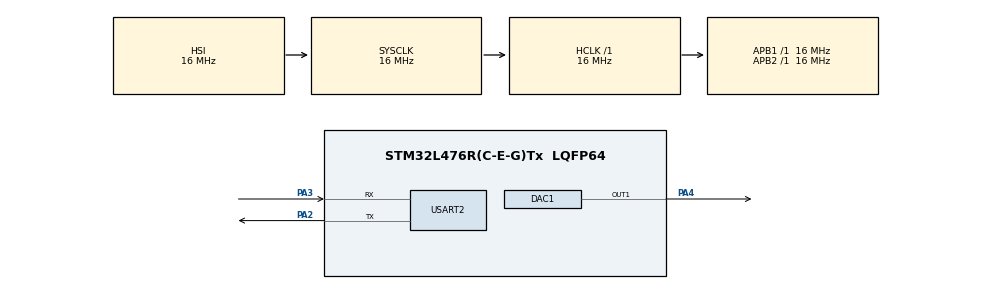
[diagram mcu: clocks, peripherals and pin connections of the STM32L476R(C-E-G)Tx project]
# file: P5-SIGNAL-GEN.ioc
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DAC1.DAC_Trigger-DAC_OUT1=DAC_TRIGGER_T2_TRGO
Dma.DAC_CH1.0.Direction=DMA_MEMORY_TO_PERIPH
Dma.DAC_CH1.0.Instance=DMA1_Channel3
Dma.DAC_CH1.0.MemDataAlignment=DMA_MDATAALIGN_WORD
Dma.DAC_CH1.0.MemInc=DMA_MINC_ENABLE
Dma.DAC_CH1.0.Mode=DMA_CIRCULAR
Dma.DAC_CH1.0.PeriphDataAlignment=DMA_PDATAALIGN_WORD
Dma.DAC_CH1.0.PeriphInc=DMA_PINC_DISABLE
Dma.DAC_CH1.0.Priority=DMA_PRIORITY_HIGH
Dma.Request0=DAC_CH1
Mcu.Family=STM32L4
Mcu.Name=STM32L476R(C-E-G)Tx
Mcu.Package=LQFP64
NVIC.DMA1_Channel3_IRQn=true\:0\:0\:false\:false\:true\:false\:true
NVIC.PriorityGroup=NVIC_PRIORITYGROUP_4
PA2.Mode=Asynchronous
PA2.Signal=USART2_TX
PA3.Mode=Asynchronous
PA3.Signal=USART2_RX
PA4.Signal=COMP_DAC11_group
ProjectManager.HeapSize=0x200
ProjectManager.StackSize=0x400
ProjectManager.TargetToolchain=STM32CubeIDE
RCC.ADCFreq_Value=16000000
RCC.AHBFreq_Value=16000000
RCC.APB1Freq_Value=16000000
RCC.APB1TimFreq_Value=16000000
RCC.APB2Freq_Value=16000000
RCC.APB2TimFreq_Value=16000000
RCC.CortexFreq_Value=16000000
RCC.HCLKFreq_Value=16000000
RCC.HSE_VALUE=8000000
RCC.HSI_VALUE=16000000
RCC.LSE_VALUE=32768
RCC.MSI_VALUE=4000000
RCC.SYSCLKFreq_VALUE=16000000
RCC.SYSCLKSource=RCC_SYSCLKSOURCE_HSI
RCC.USBFreq_Value=16000000
RCC.VCOOutputFreq_Value=32000000
SH.COMP_DAC11_group.0=DAC1_OUT1,DAC_OUT1
TIM2.TIM_MasterOutputTrigger=TIM_TRGO_UPDATE
USART2.VirtualMode-Asynchronous=VM_ASYNC
VP_TIM2_VS_ClockSourceINT.Mode=Internal
board=custom

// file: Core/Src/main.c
/* USER CODE BEGIN Header */
/**
  ******************************************************************************
  * @file           : main.c
  * @brief          : Main program body
  ******************************************************************************
  * @attention
  *
  * <h2><center>&copy; Copyright (c) 2021 STMicroelectronics.
  * All rights reserved.</center></h2>
  *
  * This software component is licensed by ST under BSD 3-Clause license,
  * the "License"; You may not use this file except in compliance with the
  * License. You may obtain a copy of the License at:
  *                        opensource.org/licenses/BSD-3-Clause
  *
  ******************************************************************************
  */
/* USER CODE END Header */
#include "main.h"

/* USER CODE BEGIN Includes */
#include "stdlib.h"
#include "string.h"
#include "stdio.h"
#include "ctype.h"
#include "math.h"
/* USER CODE END Includes */

/* USER CODE BEGIN PTD */
typedef enum {
	SQUARE,
	SINE,
	TRIANGLE
} WaveType;

typedef struct {
	WaveType type;
	int frequency;
	float logic_min;
	float logic_max;
} Wave;
/* USER CODE END PTD */

DAC_HandleTypeDef hdac1;
DMA_HandleTypeDef hdma_dac_ch1;

TIM_HandleTypeDef htim2;

UART_HandleTypeDef huart2;

/* USER CODE BEGIN PV */
uint32_t wave_buffer[WAVE_SIZE_MAX];
uint8_t str[256];
int n;
/* USER CODE END PV */

void SystemClock_Config(void);
static void MX_GPIO_Init(void);
static void MX_DMA_Init(void);
static void MX_DAC1_Init(void);
static void MX_TIM2_Init(void);
static void MX_USART2_UART_Init(void);
/* USER CODE BEGIN PFP */
void wave_gen(Wave* wave);
/* USER CODE END PFP */

int main(void)
{

  /* MCU Configuration--------------------------------------------------------*/

  /* Reset of all peripherals, Initializes the Flash interface and the Systick. */
  HAL_Init();

  /* Configure the system clock */
  SystemClock_Config();

  /* Initialize all configured peripherals */
  MX_GPIO_Init();
  MX_DMA_Init();
  MX_DAC1_Init();
  MX_TIM2_Init();
  MX_USART2_UART_Init();
  /* USER CODE BEGIN 2 */
  n = sprintf((char*) str, "Project 5 - Signal Generator by Chris Abajian (cxa6282@rit.edu)\r\n");
  HAL_UART_Transmit(&huart2, str, n, 100);
  n = sprintf((char*) str, "Starting a 1KHz square wave from 0.0V - 3.3V\r\n");
  HAL_UART_Transmit(&huart2, str, n, 100);
  n = sprintf((char*) str, "Command format: \r\n");
  HAL_UART_Transmit(&huart2, str, n, 100);
  n = sprintf((char*) str, "  > type freq minv maxv\r\n");
  HAL_UART_Transmit(&huart2, str, n, 100);
  // Initialize a 1KHz square wave.
  Wave wave = {SQUARE, 1000, LOGIC_MIN, LOGIC_MAX};
  wave_gen(&wave);
  /* USER CODE END 2 */

  /* Infinite loop */
  /* USER CODE BEGIN WHILE */
  while (1)
  {
    // Prompt
    n = sprintf((char*) str, "> ");
    HAL_UART_Transmit(&huart2, str, n, 100);

	// Wait for incoming command.
    int i = 0;
    uint8_t cmd[128];
	while (1) {
		uint8_t c;
		HAL_UART_Receive(&huart2, &c, 1, 1000000);
		if ((c == '\r') || (c == '\n')) {
			cmd[i] = 0;
			n = sprintf((char*) str, "\r\n");
			HAL_UART_Transmit(&huart2, str, n, 100);
			break;
		} else {
			HAL_UART_Transmit(&huart2, &c, 1, 100);
			cmd[i++] = c;
		}
	}

	// Parse command.
	i = 0;
	char* arg = strtok((char*)cmd, " ");
	while ((arg != NULL) && (i < 4)) {
		switch (i++) {
			// Wave type
			case 0:;
				char c = tolower(arg[0]);
				if (c == 'r') {
					wave.type = SQUARE;
				} else if (c == 's') {
					wave.type = SINE;
				} else if (c == 't') {
					wave.type = TRIANGLE;
				}
				break;
			// Wave frequency
			case 1:;
				int f = atoi(arg);
				if ((f >= WAVE_FREQ_MIN) && (f <= WAVE_FREQ_MAX))
					wave.frequency = f;
				break;
			// Wave minimum logic level
			case 2:;
				float min = atof(arg);
				if ((min >= LOGIC_MIN) && (min < LOGIC_MAX))
					wave.logic_min = min;
				break;
			// Wave maximum logic level
			case 3:;
				float max = atof(arg);
				if ((max > wave.logic_min) && (max <= LOGIC_MAX))
					wave.logic_max = max;
				break;
		}
		arg = strtok(NULL, " ");
	}

	// Generate the wave.
	wave_gen(&wave);

    /* USER CODE END WHILE */

  }
}

void SystemClock_Config(void)
{
  RCC_OscInitTypeDef RCC_OscInitStruct = {0};
  RCC_ClkInitTypeDef RCC_ClkInitStruct = {0};

  /** Configure the main internal regulator output voltage
  */
  if (HAL_PWREx_ControlVoltageScaling(PWR_REGULATOR_VOLTAGE_SCALE1) != HAL_OK)
  {
    Error_Handler();
  }
  /** Initializes the RCC Oscillators according to the specified parameters
  * in the RCC_OscInitTypeDef structure.
  */
  RCC_OscInitStruct.OscillatorType = RCC_OSCILLATORTYPE_HSI;
  RCC_OscInitStruct.HSIState = RCC_HSI_ON;
  RCC_OscInitStruct.HSICalibrationValue = RCC_HSICALIBRATION_DEFAULT;
  RCC_OscInitStruct.PLL.PLLState = RCC_PLL_NONE;
  if (HAL_RCC_OscConfig(&RCC_OscInitStruct) != HAL_OK)
  {
    Error_Handler();
  }
  /** Initializes the CPU, AHB and APB buses clocks
  */
  RCC_ClkInitStruct.ClockType = RCC_CLOCKTYPE_HCLK|RCC_CLOCKTYPE_SYSCLK
                              |RCC_CLOCKTYPE_PCLK1|RCC_CLOCKTYPE_PCLK2;
  RCC_ClkInitStruct.SYSCLKSource = RCC_SYSCLKSOURCE_HSI;
  RCC_ClkInitStruct.AHBCLKDivider = RCC_SYSCLK_DIV1;
  RCC_ClkInitStruct.APB1CLKDivider = RCC_HCLK_DIV1;
  RCC_ClkInitStruct.APB2CLKDivider = RCC_HCLK_DIV1;

  if (HAL_RCC_ClockConfig(&RCC_ClkInitStruct, FLASH_LATENCY_0) != HAL_OK)
  {
    Error_Handler();
  }
}

static void MX_DAC1_Init(void)
{

  DAC_ChannelConfTypeDef sConfig = {0};

  /** DAC Initialization
  */
  hdac1.Instance = DAC1;
  if (HAL_DAC_Init(&hdac1) != HAL_OK)
  {
    Error_Handler();
  }
  /** DAC channel OUT1 config
  */
  sConfig.DAC_SampleAndHold = DAC_SAMPLEANDHOLD_DISABLE;
  sConfig.DAC_Trigger = DAC_TRIGGER_T2_TRGO;
  sConfig.DAC_OutputBuffer = DAC_OUTPUTBUFFER_ENABLE;
  sConfig.DAC_ConnectOnChipPeripheral = DAC_CHIPCONNECT_DISABLE;
  sConfig.DAC_UserTrimming = DAC_TRIMMING_FACTORY;
  if (HAL_DAC_ConfigChannel(&hdac1, &sConfig, DAC_CHANNEL_1) != HAL_OK)
  {
    Error_Handler();
  }

}

static void MX_TIM2_Init(void)
{

  TIM_ClockConfigTypeDef sClockSourceConfig = {0};
  TIM_MasterConfigTypeDef sMasterConfig = {0};

  htim2.Instance = TIM2;
  htim2.Init.Prescaler = 0;
  htim2.Init.CounterMode = TIM_COUNTERMODE_UP;
  htim2.Init.Period = 4294967295;
  htim2.Init.ClockDivision = TIM_CLOCKDIVISION_DIV1;
  htim2.Init.AutoReloadPreload = TIM_AUTORELOAD_PRELOAD_DISABLE;
  if (HAL_TIM_Base_Init(&htim2) != HAL_OK)
  {
    Error_Handler();
  }
  sClockSourceConfig.ClockSource = TIM_CLOCKSOURCE_INTERNAL;
  if (HAL_TIM_ConfigClockSource(&htim2, &sClockSourceConfig) != HAL_OK)
  {
    Error_Handler();
  }
  sMasterConfig.MasterOutputTrigger = TIM_TRGO_UPDATE;
  sMasterConfig.MasterSlaveMode = TIM_MASTERSLAVEMODE_DISABLE;
  if (HAL_TIMEx_MasterConfigSynchronization(&htim2, &sMasterConfig) != HAL_OK)
  {
    Error_Handler();
  }

}

static void MX_USART2_UART_Init(void)
{

  huart2.Instance = USART2;
  huart2.Init.BaudRate = 115200;
  huart2.Init.WordLength = UART_WORDLENGTH_8B;
  huart2.Init.StopBits = UART_STOPBITS_1;
  huart2.Init.Parity = UART_PARITY_NONE;
  huart2.Init.Mode = UART_MODE_TX_RX;
  huart2.Init.HwFlowCtl = UART_HWCONTROL_NONE;
  huart2.Init.OverSampling = UART_OVERSAMPLING_16;
  huart2.Init.OneBitSampling = UART_ONE_BIT_SAMPLE_DISABLE;
  huart2.AdvancedInit.AdvFeatureInit = UART_ADVFEATURE_NO_INIT;
  if (HAL_UART_Init(&huart2) != HAL_OK)
  {
    Error_Handler();
  }

}

static void MX_DMA_Init(void)
{

  /* DMA controller clock enable */
  __HAL_RCC_DMA1_CLK_ENABLE();

  /* DMA interrupt init */
  /* DMA1_Channel3_IRQn interrupt configuration */
  HAL_NVIC_SetPriority(DMA1_Channel3_IRQn, 0, 0);
  HAL_NVIC_EnableIRQ(DMA1_Channel3_IRQn);

}

static void MX_GPIO_Init(void)
{

  /* GPIO Ports Clock Enable */
  __HAL_RCC_GPIOA_CLK_ENABLE();

}

/* USER CODE BEGIN 4 */
void wave_gen(Wave* wave) {
	// Set buffer size to max.
	int size = WAVE_SIZE_MAX;

	// Calculate DAC sample rate and cap at maximum.
	float freq = wave->frequency * size;
	if (freq > DAC_FREQ_MAX) {
		freq = DAC_FREQ_MAX;
		size = freq / wave->frequency;
	}

	// Populate the wave points.
	float step;
	for (int i = 0; i < size; i++) {
		switch (wave->type) {
			case SQUARE:;
				if (i < size/2) {
					wave_buffer[i] = LOGIC_TO_DAC(wave->logic_min);
				} else {
					wave_buffer[i] = LOGIC_TO_DAC(wave->logic_max);
				}
				break;
			case SINE:;
				float deg = i * (360.0 / (float)size);
				float rad = deg * (M_PI / 180.0);
				float range = (wave->logic_max - wave->logic_min) / 2.0;
				wave_buffer[i] = LOGIC_TO_DAC(wave->logic_min + range * (sin(rad) + 1));
				break;
			case TRIANGLE:;
				step = (wave->logic_max - wave->logic_min) / (size/2);
				if (i < size/2) {
					wave_buffer[i] = LOGIC_TO_DAC(wave->logic_min + (float)i*step);
				} else {
					wave_buffer[i] = LOGIC_TO_DAC(wave->logic_min + (float)(size-i)*step);
				}
				break;
		}
	}

	// Update timer auto-reload period.
    htim2.Instance->ARR = (16000000 / freq) - 1;

	// Start the DAC with DMA transfers.
	HAL_DAC_Start_DMA(&hdac1, DAC_CHANNEL_1, wave_buffer, (uint32_t)size, DAC_ALIGN_12B_R);
	// Start the timer.
	HAL_TIM_Base_Start(&htim2);

	// DEBUG: print the buffer.
	for (int i = 0; i < size; i++) {
		n = sprintf((char*)str, "%ld,", wave_buffer[i]);
		HAL_UART_Transmit(&huart2, str, n, 100);
	}
}
/* USER CODE END 4 */

void Error_Handler(void)
{
  __disable_irq();
  while (1)
  {
  }
}

/************************ (C) COPYRIGHT STMicroelectronics *****END OF FILE****/
